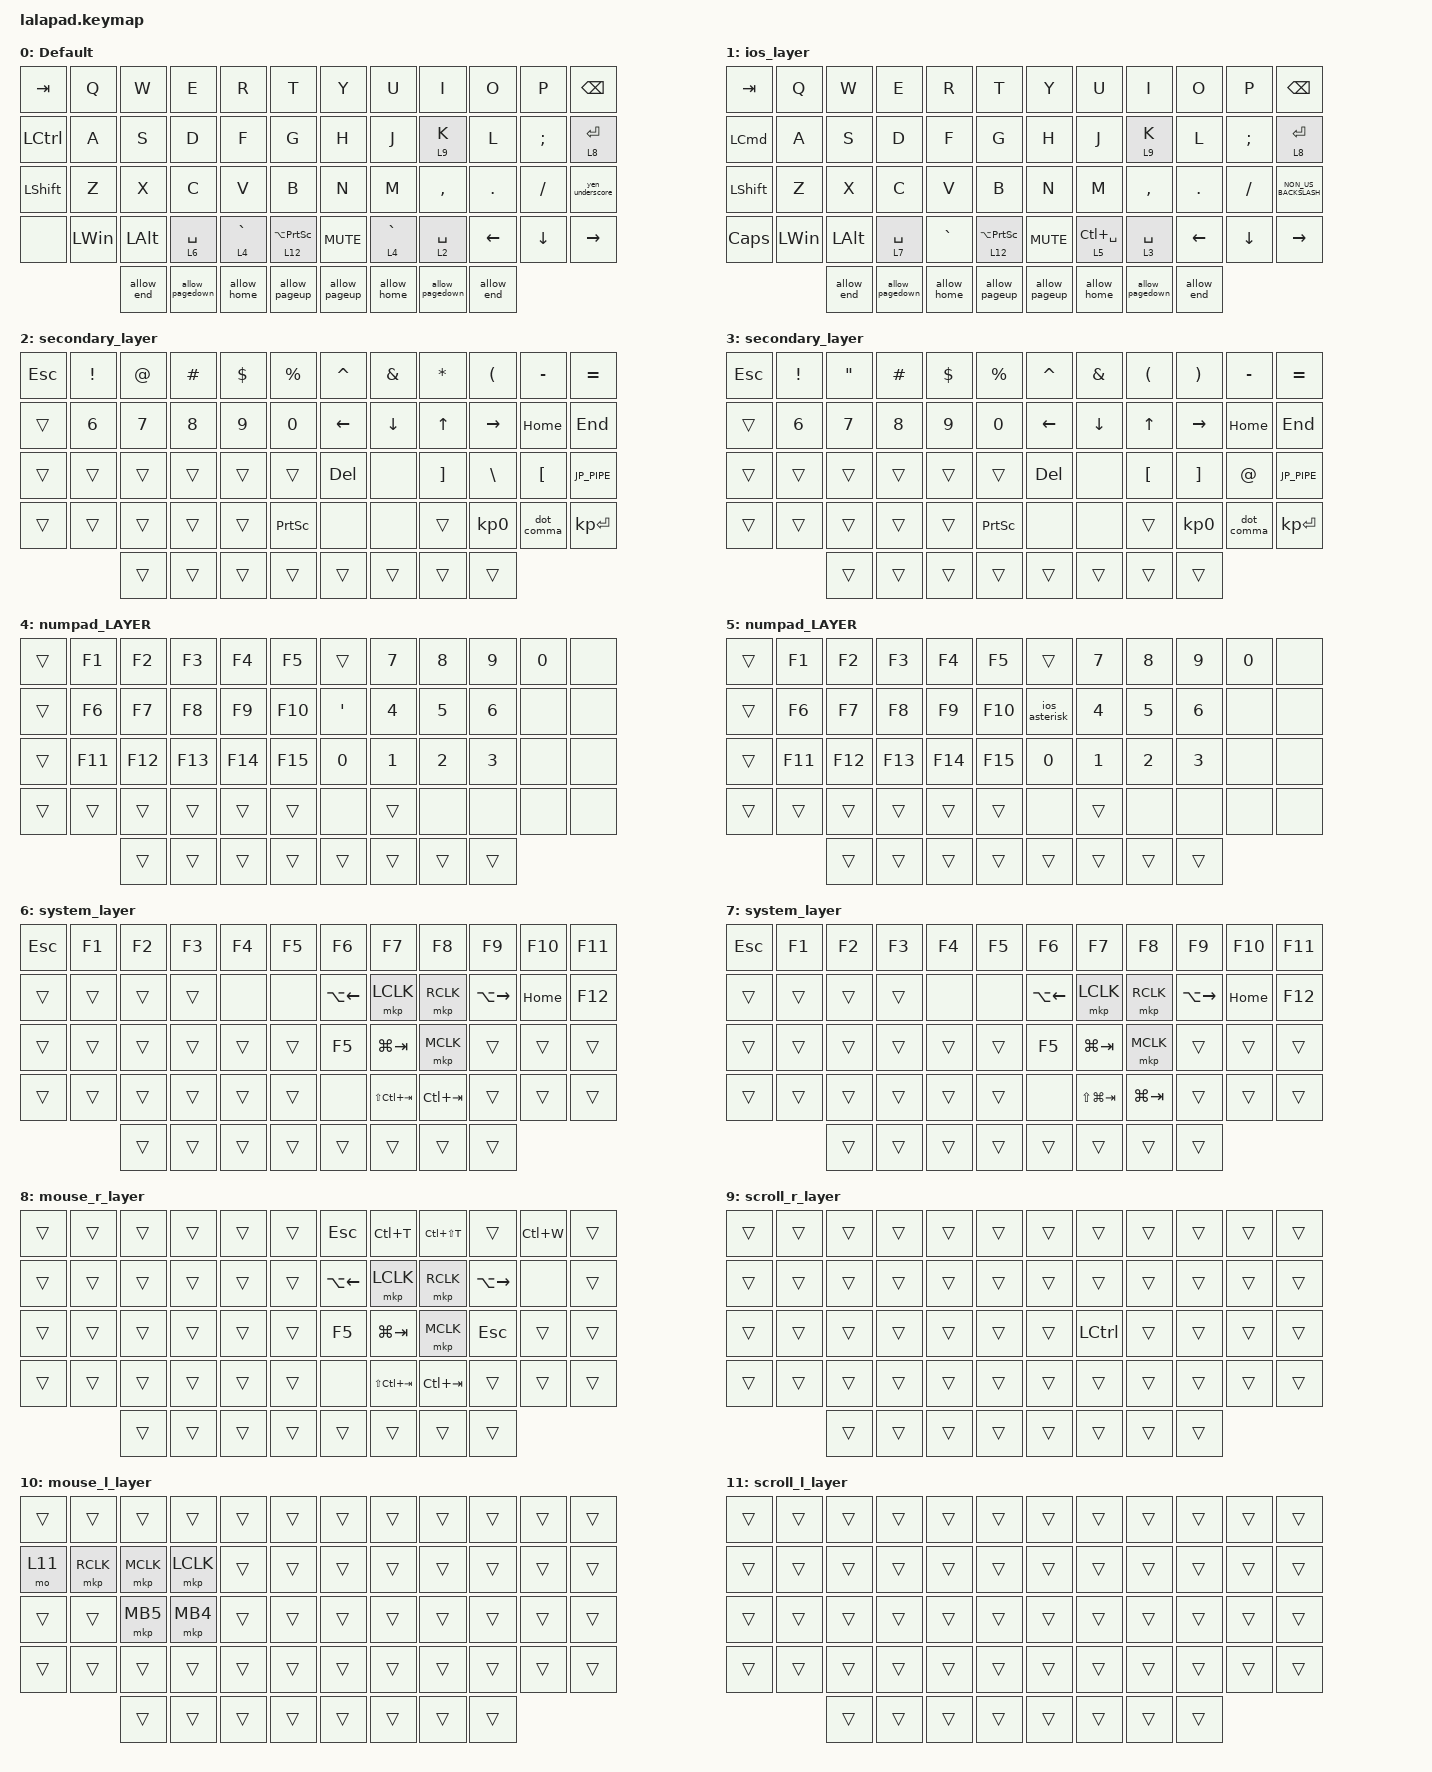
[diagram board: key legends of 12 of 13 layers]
#include <input/processors.dtsi>
#include <behaviors.dtsi>
#include <dt-bindings/zmk/bt.h>
#include <dt-bindings/zmk/keys.h>
#include <dt-bindings/zmk/pointing.h>

#define win_DEFAULT_LAYER     0
#define ios_LAYER             1
#define win_symbol_LAYER      2
#define ios_symbol_LAYER      3
#define win_numpad_LAYER      4
#define ios_numpad_LAYER      5
#define win_mouse_LAYER       6
#define ios_mouse_LAYER       7
#define MOUSE_v2_LAYER        8
#define SCROLL_R_LAYER        9
#define UNUSED_MOUSE_L_LAYER  10
#define UNUSED_SCROLL_L_LAYER 11
#define BT_LAYER              12

// Mouse Scroll Value

#define ZMK_POINTING_DEFAULT_SCRL_VAL 100

// jp key layout

#define JP_YEN          0x89              // ¥
#define JP_PIPE         LS(0x89)          // |
#define JP_UNDERSCORE   LS(0x87)          // _

// cirque trackpad input&layer control

&glidepoint_listener_R {
    input-processors =
        <&zip_xy_transform (INPUT_TRANSFORM_XY_SWAP | INPUT_TRANSFORM_X_INVERT | INPUT_TRANSFORM_Y_INVERT)>,
        // <&zip_xy_scaler 2 1>,,,,,,,,,,,,,,,,,,,,,,,,,,,,,,,,,,,,,,,,,,
        // <&zip_temp_layer MOUSE_R_LAYER 500>;,,,,,,,,,,,,,,,,,,,,,,,,,,,,,,,,,,,,,,,,,
        <&zip_xy_scaler 9 4>;

    //    lowspeedmode {
    //        layers = <SECONDARY_LAYER>;
    //        input-processors =
    //            <&zip_xy_transform (INPUT_TRANSFORM_XY_SWAP | INPUT_TRANSFORM_X_INVERT | INPUT_TRANSFORM_Y_INVERT)>,
    //            // <&zip_xy_scaler 3 4>,,
    //            // <&zip_temp_layer MOUSE_R_LAYER 500>;,
    //            <&zip_xy_scaler 3 4>;
    //    };

    scroller {
        layers = <SCROLL_R_LAYER>;
        input-processors =
            <&zip_xy_to_scroll_mapper>,
            // <&zip_scroll_transform (INPUT_TRANSFORM_XY_SWAP | INPUT_TRANSFORM_Y_INVERT)>,,,,,,,,,,,,,,,,,,,,,,,,,,,,,,,,,,,,,,,,,,
            <&zip_scroll_transform (INPUT_TRANSFORM_XY_SWAP | INPUT_TRANSFORM_X_INVERT)>,
            <&zip_scroll_scaler 1 8>;
    };
};

&glidepoint_listener_L {
    input-processors =
        <&zip_xy_transform (INPUT_TRANSFORM_XY_SWAP | INPUT_TRANSFORM_X_INVERT | INPUT_TRANSFORM_Y_INVERT)>,
        // <&zip_xy_scaler 2 1>,,,,,,,,,,,,,,,,,,,,,,,,,,,,,,,,,,,,,,,,,,
        // <&zip_temp_layer MOUSE_L_LAYER 500>;,,,,,,,,,,,,,,,,,,,,,,,,,,,,,,,,,,,,,,,,,
        <&zip_xy_scaler 9 4>;

    //    lowspeedmode {
    //        layers = <SECONDARY_LAYER>;
    //        input-processors =
    //            <&zip_xy_transform (INPUT_TRANSFORM_XY_SWAP | INPUT_TRANSFORM_X_INVERT | INPUT_TRANSFORM_Y_INVERT)>,
    //            // <&zip_xy_scaler 3 4>,,
    //            // <&zip_temp_layer MOUSE_L_LAYER 500>;,
    //            <&zip_xy_scaler 3 4>;
    //    };

    scroller {
        layers = <UNUSED_SCROLL_L_LAYER>;
        input-processors =
            <&zip_xy_to_scroll_mapper>,
            // <&zip_scroll_transform (INPUT_TRANSFORM_XY_SWAP | INPUT_TRANSFORM_Y_INVERT)>,,,,,,,,,,,,,,,,,,,,,,,,,,,,,,,,,,,,,,,,,,
            <&zip_scroll_transform (INPUT_TRANSFORM_XY_SWAP | INPUT_TRANSFORM_X_INVERT)>,
            <&zip_scroll_scaler 1 6>;
    };
};

&mt { quick-tap-ms = <200>; };

&lt { quick-tap-ms = <200>; };

/ {
    behaviors {
        // Encoder to Mouse Scroll

        scroll_up_down: sensor_scroll_up_down {
            compatible = "zmk,behavior-sensor-rotate";
            #sensor-binding-cells = <0>;
            bindings = <&msc SCRL_UP>, <&msc SCRL_DOWN>;

            tap-ms = <20>;
            label = "SCROLL_UP_DOWN";
        };

        scroll_down_up: sensor_scroll_down_up {
            compatible = "zmk,behavior-sensor-rotate";
            #sensor-binding-cells = <0>;
            bindings = <&msc SCRL_DOWN>, <&msc SCRL_UP>;

            tap-ms = <20>;
            label = "SCROLL_DOWN_UP";
        };

        scroll_left_right: sensor_scroll_left_right {
            compatible = "zmk,behavior-sensor-rotate";
            #sensor-binding-cells = <0>;
            bindings = <&msc SCRL_LEFT>, <&msc SCRL_RIGHT>;

            tap-ms = <20>;
            label = "SCROLL_LEFT_RIGHT";
        };

        scroll_right_left: sensor_scroll_right_left {
            compatible = "zmk,behavior-sensor-rotate";
            #sensor-binding-cells = <0>;
            bindings = <&msc SCRL_RIGHT>, <&msc SCRL_LEFT>;

            tap-ms = <20>;
            label = "SCROLL_RIGHT_LEFT";
        };

        volume_up_down: sensor_volume_up_down {
            compatible = "zmk,behavior-sensor-rotate";
            #sensor-binding-cells = <0>;
            bindings = <&kp C_VOLUME_UP>, <&kp C_VOLUME_DOWN>;

            tap-ms = <20>;
            label = "VOLUME_UP_DOWN";
        };

        dot_comma: dot_comma {
            compatible = "zmk,behavior-mod-morph";
            #binding-cells = <0>;
            bindings = <&kp KP_DOT>, <&kp COMMA>;

            mods = <(MOD_LSFT|MOD_RSFT)>;
            label = "DOT_COMMA";
        };

        pls_minus: pls_minus {
            compatible = "zmk,behavior-mod-morph";
            #binding-cells = <0>;
            bindings = <&kp PLUS>, <&kp MINUS>;

            mods = <(MOD_LSFT|MOD_RSFT)>;
            label = "PLS_MINUS";
        };

        allow_pageup: allow_pageup {
            compatible = "zmk,behavior-mod-morph";
            #binding-cells = <0>;
            bindings = <&kp UP>, <&kp PAGE_UP>;

            mods = <(MOD_LCTL|MOD_RCTL)>;
            label = "ALLOW_PAGEUP";
        };

        allow_pagedown: allow_pagedown {
            compatible = "zmk,behavior-mod-morph";
            #binding-cells = <0>;
            bindings = <&kp DOWN>, <&kp PAGE_DOWN>;

            mods = <(MOD_LCTL|MOD_RCTL)>;
            label = "ALLOW_PAGEDOWN";
        };

        allow_home: allow_home {
            compatible = "zmk,behavior-mod-morph";
            #binding-cells = <0>;
            bindings = <&kp LEFT>, <&kp HOME>;

            mods = <(MOD_LCTL|MOD_RCTL)>;
            label = "ALLOW_HOME";
        };

        allow_end: allow_end {
            compatible = "zmk,behavior-mod-morph";
            #binding-cells = <0>;
            bindings = <&kp RIGHT>, <&kp END>;

            mods = <(MOD_LCTL|MOD_RCTL)>;
            label = "ALLOW_END";
        };

        mt2: mod_tap2 {
            compatible = "zmk,behavior-hold-tap";
            #binding-cells = <2>;
            flavor = "tap-preferred";
            tapping-term-ms = <200>;
            quick-tap-ms = <200>;
            require-prior-idle-ms = <125>;
            bindings = <&kp>, <&kp>;
        };

        volume_down_up: volume_down_up {
            compatible = "zmk,behavior-sensor-rotate";
            #sensor-binding-cells = <0>;
            bindings = <&kp C_VOLUME_DOWN>, <&kp C_VOLUME_UP>;

            tap-ms = <20>;
            label = "VOLUME_DOWN_UP";
        };

        yen_underscore: yen_underscore {
            compatible = "zmk,behavior-mod-morph";
            label = "YEN_UNDERSCORE";
            bindings = <&kp JP_YEN>, <&kp JP_UNDERSCORE>;

            #binding-cells = <0>;
            mods = <(MOD_LSFT | MOD_RSFT)>;
        };

        ios_asterisk: ios_asterisk {
            compatible = "zmk,behavior-mod-morph";
            label = "IOS_ASTERISK";
            bindings = <&kp COLON>, <&kp ASTERISK>;

            #binding-cells = <0>;
            mods = <(MOD_LSFT|MOD_RSFT)>;
        };

        lt_num: lt_num {
            compatible = "zmk,behavior-hold-tap";
            label = "LT_NUM";
            bindings = <&mo>, <&kp>;

            #binding-cells = <2>;
            tapping-term-ms = <200>;
        };
    };

    combos {
        compatible = "zmk,combos";

        ctrl+alt+delete {
            bindings = <&kp LC(LA(DELETE))>;
            key-positions = <45 46 47>;
            timeout-ms = <3000>;
        };
    };

    macros {
        bt_win_0: change_layer {
            compatible = "zmk,behavior-macro";
            #binding-cells = <0>;
            bindings = <&bt BT_SEL 0>, <&macro_wait_time 200>, <&to 0>;

            label = "CHANGE_LAYER";
        };

        bt_win_1: bt_win_2 {
            compatible = "zmk,behavior-macro";
            #binding-cells = <0>;
            bindings = <&bt BT_SEL 1>, <&macro_wait_time 200>, <&to 0>;

            label = "BT_WIN_2";
        };

        bt_ios_3: bt_ios_1 {
            compatible = "zmk,behavior-macro";
            #binding-cells = <0>;
            bindings = <&bt BT_SEL 3>, <&macro_wait_time 200>, <&to 1>;

            label = "BT_IOS_1";
        };

        bt_ios_4: bt_ios_4 {
            compatible = "zmk,behavior-macro";
            #binding-cells = <0>;
            bindings = <&bt BT_SEL 4>, <&macro_wait_time 200>, <&to 1>;

            label = "BT_IOS_4";
        };
    };

    keymap {
        compatible = "zmk,keymap";

        win_default_LAYER {
            display-name = "Default";
            sensor-bindings = <&scroll_up_down>, <&volume_down_up>;

            bindings = <
&kp TAB         &kp Q         &kp W         &kp E            &kp R        &kp T                   &kp Y          &kp U        &kp I            &kp O       &kp P      &kp BACKSPACE
&kp LCTRL       &kp A         &kp S         &kp D            &kp F        &kp G                   &kp H          &kp J        &lt 9 K          &kp L       &kp SEMI   &lt 8 ENTER
&kp LEFT_SHIFT  &kp Z         &kp X         &kp C            &kp V        &kp B                   &kp N          &kp M        &kp COMMA        &kp PERIOD  &kp SLASH  &yen_underscore
&none           &kp LEFT_WIN  &kp LEFT_ALT  &lt 6 SPACE      &lt 4 GRAVE  &lt 12 LA(PRINTSCREEN)  &kp C_MUTE     &lt 4 GRAVE  &lt 2 SPACE      &kp LEFT    &kp DOWN   &kp RIGHT
                              &allow_end    &allow_pagedown  &allow_home  &allow_pageup           &allow_pageup  &allow_home  &allow_pagedown  &allow_end
            >;
        };

        ios_default_LAYER {
            display-name = "ios_layer";
            bindings = <
&kp TAB         &kp Q         &kp W         &kp E            &kp R        &kp T                   &kp Y          &kp U            &kp I            &kp O       &kp P      &kp BACKSPACE
&kp LCMD        &kp A         &kp S         &kp D            &kp F        &kp G                   &kp H          &kp J            &lt 9 K          &kp L       &kp SEMI   &lt 8 ENTER
&kp LEFT_SHIFT  &kp Z         &kp X         &kp C            &kp V        &kp B                   &kp N          &kp M            &kp COMMA        &kp PERIOD  &kp SLASH  &kp NON_US_BACKSLASH
&kp CAPSLOCK    &kp LEFT_WIN  &kp LEFT_ALT  &lt 7 SPACE      &kp GRAVE    &lt 12 LA(PRINTSCREEN)  &kp C_MUTE     &lt 5 LC(SPACE)  &lt 3 SPACE      &kp LEFT    &kp DOWN   &kp RIGHT
                              &allow_end    &allow_pagedown  &allow_home  &allow_pageup           &allow_pageup  &allow_home      &allow_pagedown  &allow_end
            >;

            sensor-bindings = <&scroll_up_down>, <&volume_down_up>;
        };

        win_symbol_LAYER {
            display-name = "secondary_layer";
            sensor-bindings = <&scroll_left_right>, <&scroll_left_right>;

            bindings = <
&kp ESCAPE  &kp EXCLAMATION  &kp AT        &kp HASH      &kp DOLLAR    &kp PERCENT      &kp CARET       &kp AMPERSAND   &kp ASTERISK       &kp LEFT_PARENTHESIS  &kp MINUS         &kp EQUAL
&trans      &kp NUMBER_6     &kp NUMBER_7  &kp NUMBER_8  &kp NUMBER_9  &kp NUMBER_0     &kp LEFT_ARROW  &kp DOWN_ARROW  &kp UP_ARROW       &kp RIGHT_ARROW       &kp HOME          &kp END
&trans      &trans           &trans        &trans        &trans        &trans           &kp DELETE      &none           &kp RIGHT_BRACKET  &kp BACKSLASH         &kp LEFT_BRACKET  &kp JP_PIPE
&trans      &trans           &trans        &trans        &trans        &kp PRINTSCREEN  &none           &none           &trans             &kp KP_NUMBER_0       &dot_comma        &kp KP_ENTER
                             &trans        &trans        &trans        &trans           &trans          &trans          &trans             &trans
            >;
        };

        ios_symbol_layer {
            display-name = "secondary_layer";
            bindings = <
&kp ESCAPE  &kp EXCLAMATION  &kp DOUBLE_QUOTES  &kp HASH      &kp DOLLAR    &kp PERCENT      &kp CARET       &kp AMPERSAND   &kp LEFT_PARENTHESIS  &kp RIGHT_PARENTHESIS  &kp MINUS    &kp EQUAL
&trans      &kp NUMBER_6     &kp NUMBER_7       &kp NUMBER_8  &kp NUMBER_9  &kp NUMBER_0     &kp LEFT_ARROW  &kp DOWN_ARROW  &kp UP_ARROW          &kp RIGHT_ARROW        &kp HOME     &kp END
&trans      &trans           &trans             &trans        &trans        &trans           &kp DELETE      &none           &kp LEFT_BRACKET      &kp RIGHT_BRACKET      &kp AT_SIGN  &kp JP_PIPE
&trans      &trans           &trans             &trans        &trans        &kp PRINTSCREEN  &none           &none           &trans                &kp KP_NUMBER_0        &dot_comma   &kp KP_ENTER
                             &trans             &trans        &trans        &trans           &trans          &trans          &trans                &trans
            >;

            sensor-bindings = <&scroll_left_right>, <&scroll_left_right>;
        };

        win_numpad_LAYER {
            display-name = "numpad_LAYER";
            bindings = <
&trans  &kp F1   &kp F2   &kp F3   &kp F4   &kp F5   &trans            &kp NUMBER_7  &kp NUMBER_8  &kp NUMBER_9  &kp NUMBER_0  &none
&trans  &kp F6   &kp F7   &kp F8   &kp F9   &kp F10  &kp SINGLE_QUOTE  &kp NUMBER_4  &kp N5        &kp NUMBER_6  &none         &none
&trans  &kp F11  &kp F12  &kp F13  &kp F14  &kp F15  &kp NUMBER_0      &kp NUMBER_1  &kp NUMBER_2  &kp NUMBER_3  &none         &none
&trans  &trans   &trans   &trans   &trans   &trans   &none             &trans        &none         &none         &none         &none
                 &trans   &trans   &trans   &trans   &trans            &trans        &trans        &trans
            >;

            sensor-bindings = <&inc_dec_kp 0 0>, <&scroll_up_down>;
        };

        ios_numpad_layer {
            display-name = "numpad_LAYER";
            bindings = <
&trans  &kp F1   &kp F2   &kp F3   &kp F4   &kp F5   &trans         &kp NUMBER_7  &kp NUMBER_8  &kp NUMBER_9  &kp NUMBER_0  &none
&trans  &kp F6   &kp F7   &kp F8   &kp F9   &kp F10  &ios_asterisk  &kp NUMBER_4  &kp N5        &kp NUMBER_6  &none         &none
&trans  &kp F11  &kp F12  &kp F13  &kp F14  &kp F15  &kp NUMBER_0   &kp NUMBER_1  &kp NUMBER_2  &kp NUMBER_3  &none         &none
&trans  &trans   &trans   &trans   &trans   &trans   &none          &trans        &none         &none         &none         &none
                 &trans   &trans   &trans   &trans   &trans         &trans        &trans        &trans
            >;

            sensor-bindings = <&inc_dec_kp 0 0>, <&scroll_up_down>;
        };

        win_mouse_LAYER {
            display-name = "system_layer";
            sensor-bindings = <&scroll_down_up>, <&volume_up_down>;

            bindings = <
&kp ESCAPE  &kp F1  &kp F2  &kp F3  &kp F4  &kp F5  &kp F6              &kp F7           &kp F8       &kp F9               &kp F10   &kp F11
&trans      &trans  &trans  &trans  &none   &none   &kp LA(LEFT_ARROW)  &mkp LCLK        &mkp RCLK    &kp LA(RIGHT_ARROW)  &kp HOME  &kp F12
&trans      &trans  &trans  &trans  &trans  &trans  &kp F5              &kp LG(TAB)      &mkp MCLK    &trans               &trans    &trans
&trans      &trans  &trans  &trans  &trans  &trans  &none               &kp LS(LC(TAB))  &kp LC(TAB)  &trans               &trans    &trans
                    &trans  &trans  &trans  &trans  &trans              &trans           &trans       &trans
            >;
        };

        ios_mouse_layer {
            display-name = "system_layer";
            bindings = <
&kp ESCAPE  &kp F1  &kp F2  &kp F3  &kp F4  &kp F5  &kp F6              &kp F7           &kp F8       &kp F9               &kp F10   &kp F11
&trans      &trans  &trans  &trans  &none   &none   &kp LA(LEFT_ARROW)  &mkp LCLK        &mkp RCLK    &kp LA(RIGHT_ARROW)  &kp HOME  &kp F12
&trans      &trans  &trans  &trans  &trans  &trans  &kp F5              &kp LG(TAB)      &mkp MCLK    &trans               &trans    &trans
&trans      &trans  &trans  &trans  &trans  &trans  &none               &kp LS(LG(TAB))  &kp LG(TAB)  &trans               &trans    &trans
                    &trans  &trans  &trans  &trans  &trans              &trans           &trans       &trans
            >;

            sensor-bindings = <&scroll_down_up>, <&volume_up_down>;
        };

        MOUSE_v2_LAYER {
            display-name = "mouse_r_layer";
            bindings = <
&trans  &trans  &trans  &trans  &trans  &trans  &kp ESCAPE          &kp LC(T)        &kp LC(LS(T))  &trans               &kp LC(W)  &trans
&trans  &trans  &trans  &trans  &trans  &trans  &kp LA(LEFT_ARROW)  &mkp LCLK        &mkp RCLK      &kp LA(RIGHT_ARROW)  &none      &trans
&trans  &trans  &trans  &trans  &trans  &trans  &kp F5              &kp LG(TAB)      &mkp MCLK      &kp ESCAPE           &trans     &trans
&trans  &trans  &trans  &trans  &trans  &trans  &none               &kp LS(LC(TAB))  &kp LC(TAB)    &trans               &trans     &trans
                &trans  &trans  &trans  &trans  &trans              &trans           &trans         &trans
            >;
        };

        SCROLL_R_LAYER {
            display-name = "scroll_r_layer";
            bindings = <
&trans  &trans  &trans  &trans  &trans  &trans  &trans  &trans     &trans  &trans  &trans  &trans
&trans  &trans  &trans  &trans  &trans  &trans  &trans  &trans     &trans  &trans  &trans  &trans
&trans  &trans  &trans  &trans  &trans  &trans  &trans  &kp LCTRL  &trans  &trans  &trans  &trans
&trans  &trans  &trans  &trans  &trans  &trans  &trans  &trans     &trans  &trans  &trans  &trans
                &trans  &trans  &trans  &trans  &trans  &trans     &trans  &trans
            >;
        };

        UNUSED_MOUSE_L_LAYER {
            display-name = "mouse_l_layer";
            bindings = <
&trans  &trans     &trans     &trans     &trans  &trans  &trans  &trans  &trans  &trans  &trans  &trans
&mo 11  &mkp RCLK  &mkp MCLK  &mkp LCLK  &trans  &trans  &trans  &trans  &trans  &trans  &trans  &trans
&trans  &trans     &mkp MB5   &mkp MB4   &trans  &trans  &trans  &trans  &trans  &trans  &trans  &trans
&trans  &trans     &trans     &trans     &trans  &trans  &trans  &trans  &trans  &trans  &trans  &trans
                   &trans     &trans     &trans  &trans  &trans  &trans  &trans  &trans
            >;
        };

        UNUSED_SCROLL_L_LAYER {
            display-name = "scroll_l_layer";
            bindings = <
&trans  &trans  &trans  &trans  &trans  &trans  &trans  &trans  &trans  &trans  &trans  &trans
&trans  &trans  &trans  &trans  &trans  &trans  &trans  &trans  &trans  &trans  &trans  &trans
&trans  &trans  &trans  &trans  &trans  &trans  &trans  &trans  &trans  &trans  &trans  &trans
&trans  &trans  &trans  &trans  &trans  &trans  &trans  &trans  &trans  &trans  &trans  &trans
                &trans  &trans  &trans  &trans  &trans  &trans  &trans  &trans
            >;
        };

        BT_LAYER {
            bindings = <
&trans  &bt_win_0  &bt_win_1  &bt BT_SEL 2  &bt_ios_3   &bt_ios_4  &trans  &trans  &trans  &trans  &trans  &trans
&trans  &trans     &trans     &trans        &trans      &trans     &trans  &trans  &trans  &trans  &trans  &trans
&trans  &trans     &trans     &trans        &trans      &trans     &trans  &trans  &trans  &trans  &trans  &trans
&trans  &trans     &trans     &trans        &bt BT_CLR  &trans     &trans  &trans  &trans  &trans  &trans  &trans
                   &trans     &trans        &trans      &trans     &trans  &trans  &trans  &trans
            >;
        };
    };

    conditional_layers { compatible = "zmk,conditional-layers"; };
};
